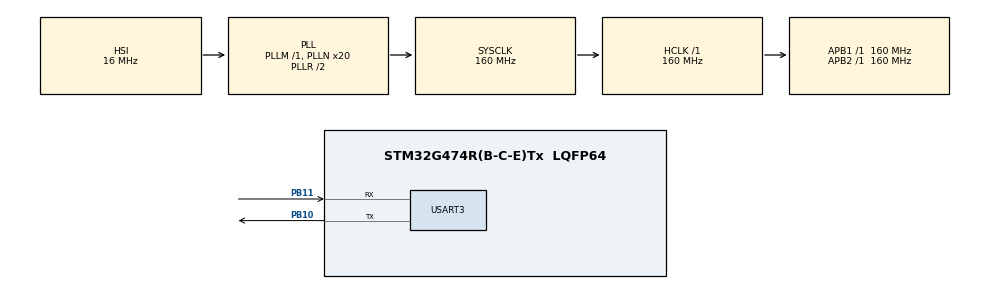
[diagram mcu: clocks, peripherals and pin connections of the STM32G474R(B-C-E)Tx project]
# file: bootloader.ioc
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Mcu.Family=STM32G4
Mcu.Name=STM32G474R(B-C-E)Tx
Mcu.Package=LQFP64
NVIC.PriorityGroup=NVIC_PRIORITYGROUP_4
NVIC.USART3_IRQn=true\:0\:0\:false\:false\:true\:true\:true\:true
PA13.Mode=Serial_Wire
PA13.Signal=SYS_JTMS-SWDIO
PA14.Mode=Serial_Wire
PA14.Signal=SYS_JTCK-SWCLK
PB10.Mode=Asynchronous
PB10.Signal=USART3_TX
PB11.Mode=Asynchronous
PB11.Signal=USART3_RX
ProjectManager.HeapSize=0x200
ProjectManager.StackSize=0x400
ProjectManager.TargetToolchain=MDK-ARM V5.32
RCC.ADC12Freq_Value=160000000
RCC.ADC345Freq_Value=160000000
RCC.AHBFreq_Value=160000000
RCC.APB1Freq_Value=160000000
RCC.APB1TimFreq_Value=160000000
RCC.APB2Freq_Value=160000000
RCC.APB2TimFreq_Value=160000000
RCC.CortexFreq_Value=160000000
RCC.EXTERNAL_CLOCK_VALUE=12288000
RCC.HCLKFreq_Value=160000000
RCC.HSE_VALUE=8000000
RCC.HSI48_VALUE=48000000
RCC.HSI_VALUE=16000000
RCC.LSE_VALUE=32768
RCC.PLLN=20
RCC.SYSCLKFreq_VALUE=160000000
RCC.SYSCLKSource=RCC_SYSCLKSOURCE_PLLCLK
RCC.USBFreq_Value=160000000
RCC.VCOOutputFreq_Value=320000000
USART3.VirtualMode-Asynchronous=VM_ASYNC
VP_SYS_VS_DBSignals.Mode=DisableDeadBatterySignals
board=custom

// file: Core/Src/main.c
/* USER CODE BEGIN Header */
/**
  ******************************************************************************
  * @file           : main.c
  * @brief          : Main program body
  ******************************************************************************
  * @attention
  *
  * Copyright (c) 2025 STMicroelectronics.
  * All rights reserved.
  *
  * This software is licensed under terms that can be found in the LICENSE file
  * in the root directory of this software component.
  * If no LICENSE file comes with this software, it is provided AS-IS.
  *
  ******************************************************************************
  */
/* USER CODE END Header */
#include "main.h"

/* USER CODE BEGIN Includes */
#include "FlashG4.h"
#include "string.h"
#include "stdlib.h"
#include <stdio.h>
/* USER CODE END Includes */

UART_HandleTypeDef huart3;

/* USER CODE BEGIN PV */
char HeaderString[] = "EB-";
char RxDataChar[1];
char RxCmdString[5] = {0};
volatile uint16_t RxCmdIndex = 0;
volatile uint8_t receive_cmd = 0;
uint32_t StartFirmwareAddress = 0x08040000;
/* USER CODE END PV */

void SystemClock_Config(void);
static void MX_GPIO_Init(void);
static void MX_USART3_UART_Init(void);

/* USER CODE BEGIN 0 */
void printDebug(char *debugText)
{
	HAL_UART_Transmit(&huart3,(uint8_t *)debugText,(uint16_t)strlen(debugText),100);
}

void HAL_UART_RxCpltCallback(UART_HandleTypeDef *huart)
{
	if(huart->Instance == USART3)
  {
	  if(RxDataChar[0] == 'u')
		{
			Set_Update_Firm_Completed(0x35);
		}
		else if(RxDataChar[0] == 'n')
		{
			Set_Update_Firm_Completed(0x37);
		}
		else {
			if (RxDataChar[0] == HeaderString[RxCmdIndex] || RxCmdIndex > 2) {			// Check data has header 'EB-'
				RxCmdString[RxCmdIndex] = RxDataChar[0];
				RxCmdIndex++;
				if(RxDataChar[0] == ';' || RxCmdIndex == 5) { // current receive each line
					receive_cmd = 1;
					RxCmdIndex = 0;
				}
			} else {
				memset(RxCmdString, 0, sizeof(RxCmdString));
				RxCmdString[0] = RxDataChar[0];
				RxCmdIndex = 1;
			}
		}
		HAL_UART_Receive_IT(&huart3, (uint8_t*)RxDataChar, 1);
  }
}
/* USER CODE END 0 */

int main(void)
{

  /* MCU Configuration--------------------------------------------------------*/

  /* Reset of all peripherals, Initializes the Flash interface and the Systick. */
  HAL_Init();

  /* Configure the system clock */
  SystemClock_Config();

  /* Initialize all configured peripherals */
  MX_GPIO_Init();
  MX_USART3_UART_Init();
  /* USER CODE BEGIN 2 */
	printDebug("Press u to enter update_firmware mode, Press n to normal boot!!!\r\n");
	HAL_UART_Receive_IT(&huart3, (uint8_t*)RxDataChar, 1);
	HAL_Delay(5000);
	if ((receive_cmd == 1) && !strcmp(RxCmdString, "EB-4;"))
		HAL_NVIC_SystemReset();
	// Read selected mode
	uint64_t tmpKey[1];
	Flash_Read_Data(0x0803F800, tmpKey, 1);
	if(tmpKey[0] == 0x35)
	{
		// Update firmware mode
		StartFirmwareAddress = 0x08020000;
	}
	else if(tmpKey[0] == 0x37)
	{
		// Normal mode
		StartFirmwareAddress = 0x08040000;
	}
	else
	{
		// Load update if can't read or invalid value
		StartFirmwareAddress = 0x08020000;
	}
	// Load program
	HAL_RCC_DeInit();
	HAL_DeInit();
	SCB->SHCSR &= ~( SCB_SHCSR_USGFAULTENA_Msk |\
	SCB_SHCSR_BUSFAULTENA_Msk | \
	SCB_SHCSR_MEMFAULTENA_Msk ) ;
	__set_MSP(*((volatile uint32_t*) StartFirmwareAddress));
	uint32_t JumpAddress = *((volatile uint32_t*) (StartFirmwareAddress + 4));
	void (*reset_handler)(void) = (void*)JumpAddress;
	reset_handler();
  /* USER CODE END 2 */

  /* Infinite loop */
  while (1)
  {

  }
}

void SystemClock_Config(void)
{
  RCC_OscInitTypeDef RCC_OscInitStruct = {0};
  RCC_ClkInitTypeDef RCC_ClkInitStruct = {0};

  /** Configure the main internal regulator output voltage
  */
  HAL_PWREx_ControlVoltageScaling(PWR_REGULATOR_VOLTAGE_SCALE1_BOOST);

  /** Initializes the RCC Oscillators according to the specified parameters
  * in the RCC_OscInitTypeDef structure.
  */
  RCC_OscInitStruct.OscillatorType = RCC_OSCILLATORTYPE_HSI;
  RCC_OscInitStruct.HSIState = RCC_HSI_ON;
  RCC_OscInitStruct.HSICalibrationValue = RCC_HSICALIBRATION_DEFAULT;
  RCC_OscInitStruct.PLL.PLLState = RCC_PLL_ON;
  RCC_OscInitStruct.PLL.PLLSource = RCC_PLLSOURCE_HSI;
  RCC_OscInitStruct.PLL.PLLM = RCC_PLLM_DIV1;
  RCC_OscInitStruct.PLL.PLLN = 20;
  RCC_OscInitStruct.PLL.PLLP = RCC_PLLP_DIV2;
  RCC_OscInitStruct.PLL.PLLQ = RCC_PLLQ_DIV2;
  RCC_OscInitStruct.PLL.PLLR = RCC_PLLR_DIV2;
  if (HAL_RCC_OscConfig(&RCC_OscInitStruct) != HAL_OK)
  {
    Error_Handler();
  }

  /** Initializes the CPU, AHB and APB buses clocks
  */
  RCC_ClkInitStruct.ClockType = RCC_CLOCKTYPE_HCLK|RCC_CLOCKTYPE_SYSCLK
                              |RCC_CLOCKTYPE_PCLK1|RCC_CLOCKTYPE_PCLK2;
  RCC_ClkInitStruct.SYSCLKSource = RCC_SYSCLKSOURCE_PLLCLK;
  RCC_ClkInitStruct.AHBCLKDivider = RCC_SYSCLK_DIV1;
  RCC_ClkInitStruct.APB1CLKDivider = RCC_HCLK_DIV1;
  RCC_ClkInitStruct.APB2CLKDivider = RCC_HCLK_DIV1;

  if (HAL_RCC_ClockConfig(&RCC_ClkInitStruct, FLASH_LATENCY_4) != HAL_OK)
  {
    Error_Handler();
  }
}

static void MX_USART3_UART_Init(void)
{

  huart3.Instance = USART3;
  huart3.Init.BaudRate = 115200;
  huart3.Init.WordLength = UART_WORDLENGTH_8B;
  huart3.Init.StopBits = UART_STOPBITS_1;
  huart3.Init.Parity = UART_PARITY_NONE;
  huart3.Init.Mode = UART_MODE_TX_RX;
  huart3.Init.HwFlowCtl = UART_HWCONTROL_NONE;
  huart3.Init.OverSampling = UART_OVERSAMPLING_16;
  huart3.Init.OneBitSampling = UART_ONE_BIT_SAMPLE_DISABLE;
  huart3.Init.ClockPrescaler = UART_PRESCALER_DIV1;
  huart3.AdvancedInit.AdvFeatureInit = UART_ADVFEATURE_NO_INIT;
  if (HAL_UART_Init(&huart3) != HAL_OK)
  {
    Error_Handler();
  }
  if (HAL_UARTEx_SetTxFifoThreshold(&huart3, UART_TXFIFO_THRESHOLD_1_8) != HAL_OK)
  {
    Error_Handler();
  }
  if (HAL_UARTEx_SetRxFifoThreshold(&huart3, UART_RXFIFO_THRESHOLD_1_8) != HAL_OK)
  {
    Error_Handler();
  }
  if (HAL_UARTEx_DisableFifoMode(&huart3) != HAL_OK)
  {
    Error_Handler();
  }

}

static void MX_GPIO_Init(void)
{

  /* GPIO Ports Clock Enable */
  __HAL_RCC_GPIOB_CLK_ENABLE();
  __HAL_RCC_GPIOA_CLK_ENABLE();

}

void Error_Handler(void)
{
  __disable_irq();
  while (1)
  {
  }
}
